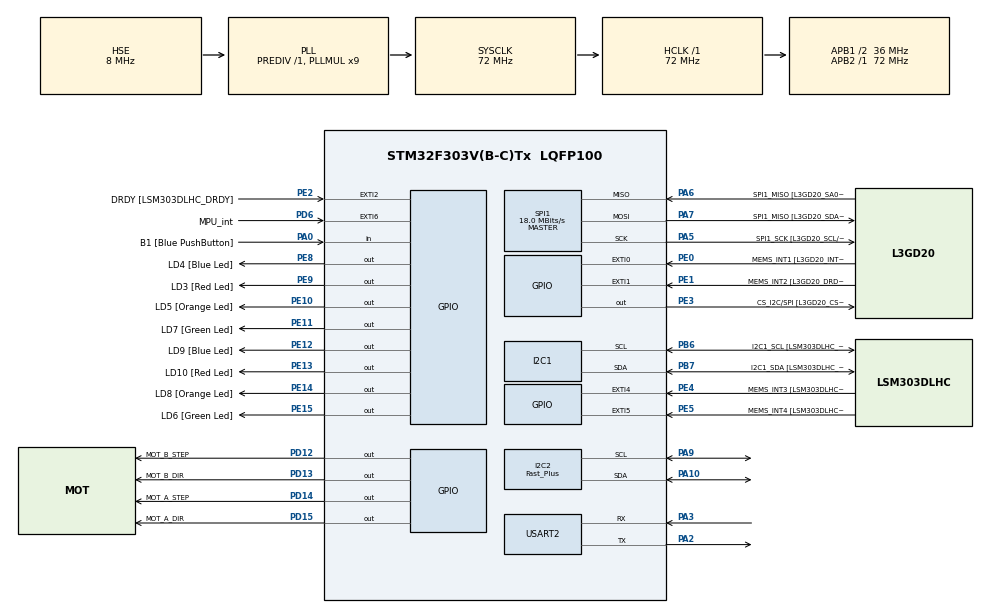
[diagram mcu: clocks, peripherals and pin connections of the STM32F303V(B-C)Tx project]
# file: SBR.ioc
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Dma.I2C2_RX.0.Direction=DMA_PERIPH_TO_MEMORY
Dma.I2C2_RX.0.Instance=DMA1_Channel5
Dma.I2C2_RX.0.MemDataAlignment=DMA_MDATAALIGN_BYTE
Dma.I2C2_RX.0.MemInc=DMA_MINC_ENABLE
Dma.I2C2_RX.0.Mode=DMA_NORMAL
Dma.I2C2_RX.0.PeriphDataAlignment=DMA_PDATAALIGN_BYTE
Dma.I2C2_RX.0.PeriphInc=DMA_PINC_DISABLE
Dma.I2C2_RX.0.Priority=DMA_PRIORITY_LOW
Dma.I2C2_TX.2.Direction=DMA_MEMORY_TO_PERIPH
Dma.I2C2_TX.2.Instance=DMA1_Channel4
Dma.I2C2_TX.2.MemDataAlignment=DMA_MDATAALIGN_BYTE
Dma.I2C2_TX.2.MemInc=DMA_MINC_ENABLE
Dma.I2C2_TX.2.Mode=DMA_NORMAL
Dma.I2C2_TX.2.PeriphDataAlignment=DMA_PDATAALIGN_BYTE
Dma.I2C2_TX.2.PeriphInc=DMA_PINC_DISABLE
Dma.I2C2_TX.2.Priority=DMA_PRIORITY_LOW
Dma.Request0=I2C2_RX
Dma.Request1=USART2_TX
Dma.Request2=I2C2_TX
Dma.Request3=USART2_RX
Dma.USART2_RX.3.Direction=DMA_PERIPH_TO_MEMORY
Dma.USART2_RX.3.Instance=DMA1_Channel6
Dma.USART2_RX.3.MemDataAlignment=DMA_MDATAALIGN_BYTE
Dma.USART2_RX.3.MemInc=DMA_MINC_ENABLE
Dma.USART2_RX.3.Mode=DMA_CIRCULAR
Dma.USART2_RX.3.PeriphDataAlignment=DMA_PDATAALIGN_BYTE
Dma.USART2_RX.3.PeriphInc=DMA_PINC_DISABLE
Dma.USART2_RX.3.Priority=DMA_PRIORITY_LOW
Dma.USART2_TX.1.Direction=DMA_MEMORY_TO_PERIPH
Dma.USART2_TX.1.Instance=DMA1_Channel7
Dma.USART2_TX.1.MemDataAlignment=DMA_MDATAALIGN_BYTE
Dma.USART2_TX.1.MemInc=DMA_MINC_ENABLE
Dma.USART2_TX.1.Mode=DMA_NORMAL
Dma.USART2_TX.1.PeriphDataAlignment=DMA_PDATAALIGN_BYTE
Dma.USART2_TX.1.PeriphInc=DMA_PINC_DISABLE
Dma.USART2_TX.1.Priority=DMA_PRIORITY_LOW
I2C1.Timing-I2C=0x2000090E
I2C2.I2C_Speed_Mode=I2C_Fast_Plus
I2C2.Timing=0x00000001
Mcu.Family=STM32F3
Mcu.Name=STM32F303V(B-C)Tx
Mcu.Package=LQFP100
NVIC.DMA1_Channel4_IRQn=true\:0\:0\:false\:false\:true\:false\:true
NVIC.DMA1_Channel5_IRQn=true\:0\:0\:false\:false\:true\:false\:true
NVIC.DMA1_Channel6_IRQn=true\:0\:0\:false\:false\:true\:false\:true
NVIC.DMA1_Channel7_IRQn=true\:0\:0\:false\:false\:true\:false\:true
NVIC.EXTI9_5_IRQn=true\:0\:0\:false\:false\:true\:true\:true
NVIC.I2C2_EV_IRQn=true\:0\:0\:false\:false\:true\:true\:true
NVIC.PriorityGroup=NVIC_PRIORITYGROUP_0
NVIC.TIM1_UP_TIM16_IRQn=true\:0\:0\:false\:false\:true\:false\:true
NVIC.TIM3_IRQn=true\:0\:0\:false\:false\:true\:true\:true
NVIC.TimeBase=TIM1_UP_TIM16_IRQn
NVIC.TimeBaseIP=TIM1
NVIC.USART2_IRQn=true\:0\:0\:false\:false\:true\:true\:true
PA0.GPIO_Label=B1 [Blue PushButton]
PA0.Signal=GPIO_Input
PA10.Mode=I2C
PA10.Signal=I2C2_SDA
PA11.GPIO_Label=DM
PA11.Signal=USB_DM
PA12.GPIO_Label=DP
PA12.Signal=USB_DP
PA13.GPIO_Label=SWDIO
PA13.Mode=Serial_Wire
PA13.Signal=SYS_JTMS-SWDIO
PA14.GPIO_Label=SWCLK
PA14.Mode=Serial_Wire
PA14.Signal=SYS_JTCK-SWCLK
PA2.Mode=Asynchronous
PA2.Signal=USART2_TX
PA3.Mode=Asynchronous
PA3.Signal=USART2_RX
PA5.GPIO_Label=SPI1_SCK [L3GD20_SCL/SPC]
PA5.Mode=Full_Duplex_Master
PA5.Signal=SPI1_SCK
PA6.GPIO_Label=SPI1_MISO [L3GD20_SA0/SDO]
PA6.Mode=Full_Duplex_Master
PA6.Signal=SPI1_MISO
PA7.GPIO_Label=SPI1_MISO [L3GD20_SDA/SDI/SDO]
PA7.Mode=Full_Duplex_Master
PA7.Signal=SPI1_MOSI
PA9.Mode=I2C
PA9.Signal=I2C2_SCL
PB3.GPIO_Label=SWO
PB3.Signal=SYS_JTDO-TRACESWO
PB6.GPIO_Label=I2C1_SCL [LSM303DLHC_SCL]
PB6.Mode=I2C
PB6.Signal=I2C1_SCL
PB7.GPIO_Label=I2C1_SDA [LSM303DLHC_SDA]
PB7.Mode=I2C
PB7.Signal=I2C1_SDA
PC14-OSC32_IN.GPIO_Label=OSC32_IN
PC14-OSC32_IN.Signal=RCC_OSC32_IN
PC15-OSC32_OUT.GPIO_Label=OSC32_OUT
PC15-OSC32_OUT.Signal=RCC_OSC32_OUT
PD12.GPIO_Label=MOT_B_STEP
PD12.Signal=GPIO_Output
PD13.GPIO_Label=MOT_B_DIR
PD13.Signal=GPIO_Output
PD14.GPIO_Label=MOT_A_STEP
PD14.Signal=GPIO_Output
PD15.GPIO_Label=MOT_A_DIR
PD15.Signal=GPIO_Output
PD6.GPIO_Label=MPU_int
PD6.Signal=GPXTI6
PE0.GPIO_Label=MEMS_INT1 [L3GD20_INT1]
PE0.GPIO_ModeDefaultEXTI=GPIO_MODE_EVT_RISING
PE0.Signal=GPXTI0
PE1.GPIO_Label=MEMS_INT2 [L3GD20_DRDY/INT2]
PE1.GPIO_ModeDefaultEXTI=GPIO_MODE_EVT_RISING
PE1.Signal=GPXTI1
PE10.GPIO_Label=LD5 [Orange Led]
PE10.Signal=GPIO_Output
PE11.GPIO_Label=LD7 [Green Led]
PE11.Signal=GPIO_Output
PE12.GPIO_Label=LD9 [Blue Led]
PE12.Signal=GPIO_Output
PE13.GPIO_Label=LD10 [Red Led]
PE13.Signal=GPIO_Output
PE14.GPIO_Label=LD8 [Orange Led]
PE14.Signal=GPIO_Output
PE15.GPIO_Label=LD6 [Green Led]
PE15.Signal=GPIO_Output
PE2.GPIO_Label=DRDY [LSM303DLHC_DRDY]
PE2.GPIO_ModeDefaultEXTI=GPIO_MODE_EVT_RISING
PE2.Signal=GPXTI2
PE3.GPIO_Label=CS_I2C/SPI [L3GD20_CS_I2C/SPI]
PE3.Signal=GPIO_Output
PE4.GPIO_Label=MEMS_INT3 [LSM303DLHC_INT1]
PE4.GPIO_ModeDefaultEXTI=GPIO_MODE_EVT_RISING
PE4.Signal=GPXTI4
PE5.GPIO_Label=MEMS_INT4 [LSM303DLHC_INT2]
PE5.GPIO_ModeDefaultEXTI=GPIO_MODE_EVT_RISING
PE5.Signal=GPXTI5
PE8.GPIO_Label=LD4 [Blue Led]
PE8.Signal=GPIO_Output
PE9.GPIO_Label=LD3 [Red Led]
PE9.Signal=GPIO_Output
PF0-OSC_IN.GPIO_Label=OSC_IN
PF0-OSC_IN.Mode=HSE-External-Clock-Source
PF0-OSC_IN.Signal=RCC_OSC_IN
PF1-OSC_OUT.GPIO_Label=OSC_OUT
PF1-OSC_OUT.Signal=RCC_OSC_OUT
ProjectManager.HeapSize=0x200
ProjectManager.StackSize=0x400
ProjectManager.TargetToolchain=Other Toolchains (GPDSC)
RCC.AHBFreq_Value=72000000
RCC.APB1CLKDivider=RCC_HCLK_DIV2
RCC.APB1Freq_Value=36000000
RCC.APB1TimFreq_Value=72000000
RCC.APB2Freq_Value=72000000
RCC.APB2TimFreq_Value=72000000
RCC.CortexFreq_Value=72000000
RCC.HCLKFreq_Value=72000000
RCC.HSE_VALUE=8000000
RCC.HSI_VALUE=8000000
RCC.LSE_VALUE=32768
RCC.PLLMUL=RCC_PLL_MUL9
RCC.PLLSourceVirtual=RCC_PLLSOURCE_HSE
RCC.PRESCALERUSB=RCC_USBCLKSOURCE_PLL_DIV1_5
RCC.SYSCLKFreq_VALUE=72000000
RCC.SYSCLKSourceVirtual=RCC_SYSCLKSOURCE_PLLCLK
RCC.USBFreq_Value=48000000
SPI1.BaudRatePrescaler=SPI_BAUDRATEPRESCALER_4
SPI1.BaudRatePrescaler-Full_Duplex_Master=SPI_BAUDRATEPRESCALER_2
SPI1.CalculateBaudRate=18.0 MBits/s
SPI1.CalculateBaudRate-Full_Duplex_Master=24.0 MBits/s
SPI1.Direction=SPI_DIRECTION_2LINES
SPI1.Mode=SPI_MODE_MASTER
SPI1.Mode-Full_Duplex_Master=SPI_MODE_MASTER
SPI1.VirtualType=VM_MASTER
USART2.VirtualMode-Asynchronous=VM_ASYNC
VP_CRC_VS_CRC.Mode=CRC_Activate
VP_SYS_VS_tim1.Mode=TIM1
VP_TIM3_VS_ClockSourceINT.Mode=Internal
board=STM32F3DISCOVERY

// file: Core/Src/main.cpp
/* USER CODE BEGIN Header */
/**
  ******************************************************************************
  * @file           : main.c
  * @brief          : Main program body
  ******************************************************************************
  * @attention
  *
  * <h2><center>&copy; Copyright (c) 2023 STMicroelectronics.
  * All rights reserved.</center></h2>
  *
  * This software component is licensed by ST under BSD 3-Clause license,
  * the "License"; You may not use this file except in compliance with the
  * License. You may obtain a copy of the License at:
  *                        opensource.org/licenses/BSD-3-Clause
  *
  ******************************************************************************
  */
/* USER CODE END Header */
#include "main.h"
#include <string.h>
#include "mpu6050.h"
#include "ssd1306.h"
#include "PID.h"
#include "stdio.h"
/* USER CODE BEGIN Includes */

#define PPR   1600
// #define TICKS_PER_SECOND  40000 // 40kHz
#define TICKS_PER_SECOND  50000 // 50kHz
#define PULSE_WIDTH 1

#define MAX_ACCEL (200)
#define ANGLE_Kp  450.0
#define ANGLE_Kd  30.0
#define ANGLE_Ki  0.0
#define MAX_ACCEL (200)

#define VELOCITY_Kp  0.007
#define VELOCITY_Kd  0.0
#define VELOCITY_Ki  0.0005
#define WARMUP_DELAY_US (5000000UL)
#define DEG_TO_RAD  0.017453292519943295769236907684886
#define RAD_TO_DEG  57.295779513082320876798154814105
#define ANGLE_SET_POINT (2.0 * DEG_TO_RAD)
#define constrain(amt,low,high) ((amt)<(low)?(low):((amt)>(high)?(high):(amt)))

#define MAX_PACKET_SIZE 96
#define DIVISOR 10000.0

CRC_HandleTypeDef hcrc;

I2C_HandleTypeDef hi2c1;
I2C_HandleTypeDef hi2c2;
DMA_HandleTypeDef hdma_i2c2_rx;
DMA_HandleTypeDef hdma_i2c2_tx;
SPI_HandleTypeDef hspi1;
TIM_HandleTypeDef htim3;
UART_HandleTypeDef huart2;
DMA_HandleTypeDef hdma_usart2_tx;
DMA_HandleTypeDef hdma_usart2_rx;

/* USER CODE BEGIN PV */
int16_t acc_x, acc_y, acc_z, gyr_x, gyr_y, gyr_z;
float ax, ay, az, gx, gy, gz, temperature, roll, pitch;
uint8_t buffer[128];

volatile bool i2c2_transmit_complete = false;
volatile bool i2c2_receive_complete = false;

volatile bool mpuInterrupt = false;

uint8_t fifoBuffer[64];

Quaternion q; // [w, x, y, z]         quaternion container
VectorFloat gravity; // [x, y, z]            gravity vector
float ypr[3]; // [yaw, pitch, roll]   yaw/pitch/roll container and gravity vector

PID anglePID(ANGLE_Kp, ANGLE_Kd, ANGLE_Ki, ANGLE_SET_POINT);
PID velocityPID(VELOCITY_Kp, VELOCITY_Kd, VELOCITY_Ki, 0.0);

float pid_settings[6] = {
	ANGLE_Kp,
	ANGLE_Kd,
	ANGLE_Ki,
	VELOCITY_Kp,
	VELOCITY_Kd,
	VELOCITY_Ki
};

volatile unsigned long currentTickLeft = 0UL;
volatile unsigned long currentTickRight = 0UL;
volatile unsigned long ticksPerPulseLeft = (unsigned long)UINT64_MAX;
volatile unsigned long ticksPerPulseRight = (unsigned long)UINT64_MAX;
volatile float accel = 0.0;
volatile float velocity = 0.0;

float joystick[2] = { 0.0f, 0.0f };
float ref_velocity = 0.0f;
float ref_steering = 0.0f;
float steering = 0.0f;

float angle = 0.0;
float targetAngle = ANGLE_SET_POINT;

float targetVelocity = 0.0;

bool isBalancing = false;

char packet[MAX_PACKET_SIZE];
uint8_t packet_size = 0;

/*uint8_t rxBuffer[64];
uint8_t rxByte;
uint16_t rxIdx;
uint8_t rxFlag;*/

#define CIRC_BUF_SZ       64  /* must be power of two */
static uint8_t rx_dma_circ_buf[CIRC_BUF_SZ];
#define DMA_WRITE_PTR ( (CIRC_BUF_SZ - huart2.hdmarx->Instance->CNDTR) & (CIRC_BUF_SZ - 1) )
static uint32_t rd_ptr;
/* USER CODE END PV */

void SystemClock_Config(void);
static void MX_GPIO_Init(void);
static void MX_DMA_Init(void);
static void MX_I2C1_Init(void);
static void MX_SPI1_Init(void);
static void MX_I2C2_Init(void);
static void MX_USART2_UART_Init(void);
static void MX_CRC_Init(void);
static void MX_TIM3_Init(void);

uint32_t getCurrentMicros(void)
{
	uint32_t m0 = HAL_GetTick();
	__IO uint32_t u0 = SysTick->VAL;
	uint32_t m1 = HAL_GetTick();
	__IO uint32_t u1 = SysTick->VAL;
	const uint32_t tms = SysTick->LOAD + 1;

	if (m1 != m0) {
		return (m1 * 1000 + ((tms - u1) * 1000) / tms);
	}
	else {
		return (m0 * 1000 + ((tms - u0) * 1000) / tms);
	}
}

void UART2_SendString(char* s)
{
	HAL_UART_Transmit(&huart2, (uint8_t*)s, strlen(s), 1000);
}

void send_float_array(float *a, uint8_t size) {
	char MSG[40] = { '\0' };
	for (int i = 0; i < size; i++) {
		sprintf(MSG, "%.2ld", (long)(a[i] * DIVISOR));
		//Serial.print((long)(a[i] * DIVISOR));
		UART2_SendString(MSG);
		if (i < size - 1) {
			MSG[0] = ';';
			MSG[1] = '\0';
			UART2_SendString(MSG);
			//Serial.print(';');
		}
	}
	//Serial.print("\r\n");
	MSG[0] = '\r';
	MSG[1] = '\n';
	MSG[1] = '\0';
	UART2_SendString(MSG);
}

void logDisplay(unsigned long nowMicros) {
	char MSG[40] = { '\0' };
	static unsigned long timestamp = HAL_GetTick();
	if (nowMicros - timestamp < 10000 /* 100Hz */) {
		return;
	}
	HAL_GPIO_TogglePin(GPIOE, LD3_Pin);

	ssd1306_Clear();

	//sprintf((char*)buffer, "ACC: X: %.2f Y:%.2f Z:%.2f \n\rGYR: X: %.2f Y:%.2f Z:%.2f\n\rTEMP: %.2f\n\r", ax, ay, az, gx, gy, gz, temperature);

	sprintf(MSG, "Angle: %.2f", angle * RAD_TO_DEG);
	ssd1306_SetCursor(0, 0);
	ssd1306_WriteString(MSG, Font_7x10);

	sprintf(MSG, "TAngle: %.2f", targetAngle * RAD_TO_DEG);
	ssd1306_SetCursor(0, 10);
	ssd1306_WriteString(MSG, Font_7x10);

	sprintf(MSG, "Velocity: %.4f", ref_velocity);
	ssd1306_SetCursor(0, 20);
	ssd1306_WriteString(MSG, Font_7x10);

	//sprintf((char*)buffer, "RPY: Roll: %.2f Pitch: %.2f\n\r\n\r", roll, pitch);

	sprintf(MSG, "Steering: %.4f", ref_steering);
	ssd1306_SetCursor(0, 30);
	ssd1306_WriteString(MSG, Font_7x10);

	/*sprintf(MSG, "Gy: %8.4f", ((s32)gy) * 2000.0 / 32768);
	ssd1306_SetCursor(0, 40);
	ssd1306_WriteString(MSG, Font_7x10);

	sprintf(MSG, "Gz: %8.4f", ((s32)gz) * 2000.0 / 32768);
	ssd1306_SetCursor(0, 50);
	ssd1306_WriteString(MSG, Font_7x10);
	ssd1306_UpdateScreen();
	//timestamp = nowMicros;

	printf("accel: (%8.4f, %8.4f, %8.4f)     gyro: (%12.4f, %12.4f, %12.4f)\r\n",
		((s32)ax) * 16.0 / 32768,
		((s32)ay) * 16.0 / 32768,
		((s32)az) * 16.0 / 32768,
		((s32)gx) * 2000.0 / 32768,
		((s32)gy) * 2000.0 / 32768,
		((s32)gz) * 2000.0 / 32768);*/

	/*float t = (float)(targetAngle * RAD_TO_DEG);
	sprintf(MSG, "a0: %.4f", t);
	ssd1306_SetCursor(0, 0);
	ssd1306_WriteString(MSG, Font_7x10);

	t = (float)(angle * RAD_TO_DEG);
	sprintf(MSG, "ta: %.4f", t);
	ssd1306_SetCursor(0, 10);
	ssd1306_WriteString(MSG, Font_7x10);

	sprintf(MSG, "tv: %.4f", velocity);
	ssd1306_SetCursor(0, 20);
	ssd1306_WriteString(MSG, Font_7x10);

	sprintf(MSG, "tu: %.4f", accel);
	ssd1306_SetCursor(0, 30);
	ssd1306_WriteString(MSG, Font_7x10);
	ssd1306_UpdateScreen();
	timestamp = nowMicros;*/
	timestamp = nowMicros;
	ssd1306_UpdateScreen();
}

void initMPU() {
	const int16_t accel_offset[3] = { -1262, -307, 1897 };
	const int16_t gyro_offset[3] = { 23, -41, 49 };

	if (MPU6050_Init(&hi2c2)) {
		ssd1306_Clear();
		ssd1306_SetCursor(0, 0);
		ssd1306_WriteString("MPU: OK", Font_7x10);
		ssd1306_UpdateScreen();

	}
	else {
		ssd1306_Clear();
		ssd1306_SetCursor(0, 0);
		ssd1306_WriteString("MPU: FAULT", Font_7x10);
		ssd1306_UpdateScreen();
		while (1)
		{}
	}

	HAL_Delay(1000);

	if (!MPU6050_dmpInitialize()) {
		ssd1306_SetCursor(0, 10);
		ssd1306_WriteString("DMP: OK", Font_7x10);
		ssd1306_UpdateScreen();

	}
	else {
		ssd1306_SetCursor(0, 10);
		ssd1306_WriteString("DMP: FAULT", Font_7x10);
		ssd1306_UpdateScreen();
		while (1)
		{}
	}

	HAL_Delay(1000);

	//MPU6050_dmpInitialize();

	/*mpu.setXGyroOffset(gyro_offset[0]);
	mpu.setYGyroOffset(gyro_offset[1]);
	mpu.setZGyroOffset(gyro_offset[2]);
	mpu.setXAccelOffset(accel_offset[0]);
	mpu.setYAccelOffset(accel_offset[1]);
	mpu.setZAccelOffset(accel_offset[2]);*/

	MPU6050_setDMPEnabled(true);
	/* EXTI interrupt init*/
	HAL_NVIC_SetPriority(EXTI9_5_IRQn, 0, 0);
	HAL_NVIC_EnableIRQ(EXTI9_5_IRQn);
}

bool mpuUpdate() {
	if (mpuInterrupt && MPU6050_GetCurrentFIFOPacket(fifoBuffer, dmpPacketSize)) {
		MPU6050_dmpGetQuaternion(&q, fifoBuffer);
		MPU6050_dmpGetGravity(&gravity, &q);
		MPU6050_dmpGetYawPitchRoll(ypr, &q, &gravity);
		mpuInterrupt = false;
		return true;
	}
	return false;
}

unsigned long getTicksPerPulse(float velocity) {
	if (abs(velocity) < 1e-3) {
		// TODO: disable motor
		return (unsigned long)UINT64_MAX ;
	}
	else {
		return (uint64_t)(2.0 * M_PI * TICKS_PER_SECOND / (abs(velocity) * PPR)) - PULSE_WIDTH;
	}
}
void updateVelocity(unsigned long nowMicros) {
	// static unsigned long counter = 0;
	// static unsigned long sum = 0;

	static unsigned long timestamp = getCurrentMicros();
	if (nowMicros - timestamp < 100 /* 10kHz */) {
		return;
	}

	// sum += (nowMicros - timestamp);
	// counter++;
	// if (counter >= 1000) {
	//   Serial.println(((float)(sum)) / counter);
	//   counter = 0;
	//   sum = 0;
	// }

	float dt = ((float)(nowMicros - timestamp)) * 1e-6;
	velocity += accel * dt;

	float leftVelocity = velocity - steering;
	float rightVelocity = velocity + steering;
	ticksPerPulseLeft = getTicksPerPulse(leftVelocity);
	ticksPerPulseRight = getTicksPerPulse(rightVelocity);

	if (leftVelocity > 0) {
		//digitalWrite(MOT_A_DIR, HIGH);
		HAL_GPIO_WritePin(GPIOD, MOT_A_DIR_Pin, GPIO_PIN_SET);

	}
	else {
		HAL_GPIO_WritePin(GPIOD, MOT_A_DIR_Pin, GPIO_PIN_RESET);
		//digitalWrite(MOT_A_DIR, LOW);
	}

	if (rightVelocity > 0) {
		HAL_GPIO_WritePin(GPIOD, MOT_B_DIR_Pin, GPIO_PIN_RESET);
		//digitalWrite(MOT_B_DIR, LOW);
	}
	else {
		HAL_GPIO_WritePin(GPIOD, MOT_B_DIR_Pin, GPIO_PIN_SET);
		//digitalWrite(MOT_B_DIR, HIGH);
	}

	timestamp = nowMicros;
}

float absF(float value)
{
	return value < 0 ? -value : value;
}

void updateControl(unsigned long nowMicros) {
	/* Wait until IMU filter will settle */
	if (nowMicros < WARMUP_DELAY_US) {
		return;
	}

	static unsigned long timestamp = HAL_GetTick();
	if (nowMicros - timestamp < 1000 /* 1kHz */) {
		return;
	}
	if (!mpuUpdate()) {
		return;
	}
	angle = ypr[1];

	float dt = ((float)(nowMicros - timestamp)) * 1e-6;
	float tmpangle = absF(angle - targetAngle);
	if (tmpangle < M_PI / 18) {
		isBalancing = true;
	}

	if (tmpangle > M_PI / 4) {
		isBalancing = false;
		accel = 0.0;
		velocity = 0.0;
	}

	if (!isBalancing) {
		return;
	}
	targetAngle = -velocityPID.getControl(velocity, dt);
	anglePID.setTarget(targetAngle);

	accel = anglePID.getControl(angle, dt);
	accel = constrain(accel, -MAX_ACCEL, MAX_ACCEL);

	timestamp = nowMicros;
}

void initMotors() {

	HAL_GPIO_WritePin(GPIOD, MOT_A_STEP_Pin, GPIO_PIN_RESET);
	HAL_GPIO_WritePin(GPIOD, MOT_B_STEP_Pin, GPIO_PIN_RESET);
	HAL_GPIO_WritePin(GPIOD, MOT_ENABLE_Pin, GPIO_PIN_RESET);
}

void parse_float_array(char *p, uint8_t p_size, float *dest) {
	char buf[16];
	long value;
	uint8_t buf_size = 0;
	uint8_t index = 0;
	for (uint8_t i = 0; i < p_size; i++) {
		if ((p[i] >= '0' && p[i] <= '9') || p[i] == '+' || p[i] == '-') {
			buf[buf_size++] = p[i];
		}
		else if (p[i] == ';') {
			buf[buf_size] = '\0';
			buf_size = 0;
			value = atol(buf);
			dest[index++] = ((float)value) / DIVISOR;
		}
	}
	buf[buf_size] = '\0';
	value = atol(buf);
	dest[index] = ((float)value) / DIVISOR;
}

void parse_settings(char *p, uint8_t p_size) {
	parse_float_array(p, p_size, pid_settings);
	anglePID.setSettings(pid_settings[0], pid_settings[1], pid_settings[2]);
	velocityPID.setSettings(pid_settings[3], pid_settings[4], pid_settings[5]);
}

void parse_control(char *p, uint8_t p_size) {
	parse_float_array(p, p_size, joystick);
	ref_velocity = joystick[0];
	ref_steering = joystick[1];
}

void handle_packet(char *p, uint8_t p_size) {
	switch (p[0]) {
	case 'r':
		send_float_array(pid_settings, 6);
		break;
	case 's':
		parse_settings(&p[1], p_size - 1);
		send_float_array(pid_settings, 6);
		break;
	case 'c':
		parse_control(&p[1], p_size - 1);
		//send_float_array(joystick, 2);
		break;
	}
}

static bool msgrx_circ_buf_is_empty(void) {
	if (rd_ptr == DMA_WRITE_PTR) {
		return true;
	}
	return false;
}

static uint8_t msgrx_circ_buf_get(void) {
	uint8_t c = 0;
	if (rd_ptr != DMA_WRITE_PTR) {
		c = rx_dma_circ_buf[rd_ptr++];
		rd_ptr &= (CIRC_BUF_SZ - 1);
	}
	return c;
}
int main(void)
{

	/* MCU Configuration--------------------------------------------------------*/

	/* Reset of all peripherals, Initializes the Flash interface and the Systick. */
	HAL_Init();

	/* Configure the system clock */
	SystemClock_Config();

	/* Initialize all configured peripherals */
	MX_GPIO_Init();
	MX_DMA_Init();
	MX_I2C1_Init();
	MX_SPI1_Init();
	MX_I2C2_Init();
	MX_USART2_UART_Init();
	MX_CRC_Init();
	MX_TIM3_Init();
	/* USER CODE BEGIN 2 */
	ssd1306_Init();
	ssd1306_FlipScreenVertically();
	ssd1306_Clear();
	ssd1306_SetColor(White);

	ssd1306_DrawRect(0, 0, ssd1306_GetWidth(), ssd1306_GetHeight());
	ssd1306_SetCursor(8, 20);
	ssd1306_WriteString("MPU6050", Font_16x26);
	ssd1306_UpdateScreen();
	HAL_Delay(2000);
	ssd1306_Clear();
	ssd1306_UpdateScreen();
	ssd1306_Clear();
	ssd1306_SetCursor(0, 0);
	ssd1306_WriteString("* FIRMWARE RESET *", Font_7x10);
	ssd1306_UpdateScreen();

	initMPU();
	initMotors();
	/* USER CODE END 2 */
	HAL_TIM_Base_Start_IT(&htim3);

	HAL_NVIC_SetPriority(USART2_IRQn, 0, 0);
	HAL_NVIC_EnableIRQ(USART2_IRQn);
	HAL_UART_Receive_DMA(&huart2, rx_dma_circ_buf, CIRC_BUF_SZ);

	/* Infinite loop */
	/* USER CODE BEGIN WHILE */
	while (1)
	{
		unsigned long now = getCurrentMicros();
		updateVelocity(now);
		updateControl(now);
#ifdef LOGGING_ENABLED
		logDisplay(now);
#endif

#ifdef COUNT_LOOP
		static unsigned long last_ts = micros();
		static unsigned long  counter = 0;

		counter++;
		if (now - last_ts >= 1000000) {
			Serial.println(counter);
			counter = 0;
			last_ts = now;
		}
#endif

		while (!msgrx_circ_buf_is_empty())
		{
			uint8_t c = msgrx_circ_buf_get();
			//HAL_UART_Receive(&huart2, &c, 1, 1000);

			if (c == '\n') {
				continue;
			}
			else if (c == '\r') {
				handle_packet(packet, packet_size);
				packet_size = 0;
			}
			else {
				packet[packet_size++] = (uint8_t) c;
			}
		}
		static const float a = 0.99;
		targetVelocity = a * targetVelocity + (1.0 - a) * ref_velocity;
		velocityPID.setTarget(targetVelocity);

		steering = a * steering + (1.0 - a) * ref_steering;
	}
	/* USER CODE END 3 */
}

void SystemClock_Config(void)
{
	RCC_OscInitTypeDef RCC_OscInitStruct = { 0 };
	RCC_ClkInitTypeDef RCC_ClkInitStruct = { 0 };
	RCC_PeriphCLKInitTypeDef PeriphClkInit = { 0 };

	/** Initializes the RCC Oscillators according to the specified parameters
	* in the RCC_OscInitTypeDef structure.
	*/
	RCC_OscInitStruct.OscillatorType = RCC_OSCILLATORTYPE_HSI | RCC_OSCILLATORTYPE_HSE;
	RCC_OscInitStruct.HSEState = RCC_HSE_BYPASS;
	RCC_OscInitStruct.HSEPredivValue = RCC_HSE_PREDIV_DIV1;
	RCC_OscInitStruct.HSIState = RCC_HSI_ON;
	RCC_OscInitStruct.HSICalibrationValue = RCC_HSICALIBRATION_DEFAULT;
	RCC_OscInitStruct.PLL.PLLState = RCC_PLL_ON;
	RCC_OscInitStruct.PLL.PLLSource = RCC_PLLSOURCE_HSE;
	RCC_OscInitStruct.PLL.PLLMUL = RCC_PLL_MUL9;
	if (HAL_RCC_OscConfig(&RCC_OscInitStruct) != HAL_OK)
	{
		Error_Handler();
	}
	/** Initializes the CPU, AHB and APB buses clocks
	*/
	RCC_ClkInitStruct.ClockType = RCC_CLOCKTYPE_HCLK | RCC_CLOCKTYPE_SYSCLK
	                            | RCC_CLOCKTYPE_PCLK1 | RCC_CLOCKTYPE_PCLK2;
	RCC_ClkInitStruct.SYSCLKSource = RCC_SYSCLKSOURCE_PLLCLK;
	RCC_ClkInitStruct.AHBCLKDivider = RCC_SYSCLK_DIV1;
	RCC_ClkInitStruct.APB1CLKDivider = RCC_HCLK_DIV2;
	RCC_ClkInitStruct.APB2CLKDivider = RCC_HCLK_DIV1;

	if (HAL_RCC_ClockConfig(&RCC_ClkInitStruct, FLASH_LATENCY_2) != HAL_OK)
	{
		Error_Handler();
	}
	PeriphClkInit.PeriphClockSelection = RCC_PERIPHCLK_USART2 | RCC_PERIPHCLK_I2C1
	                            | RCC_PERIPHCLK_I2C2;
	PeriphClkInit.Usart2ClockSelection = RCC_USART2CLKSOURCE_PCLK1;
	PeriphClkInit.I2c1ClockSelection = RCC_I2C1CLKSOURCE_HSI;
	PeriphClkInit.I2c2ClockSelection = RCC_I2C2CLKSOURCE_HSI;
	if (HAL_RCCEx_PeriphCLKConfig(&PeriphClkInit) != HAL_OK)
	{
		Error_Handler();
	}
}

static void MX_CRC_Init(void)
{

	hcrc.Instance = CRC;
	hcrc.Init.DefaultPolynomialUse = DEFAULT_POLYNOMIAL_ENABLE;
	hcrc.Init.DefaultInitValueUse = DEFAULT_INIT_VALUE_ENABLE;
	hcrc.Init.InputDataInversionMode = CRC_INPUTDATA_INVERSION_NONE;
	hcrc.Init.OutputDataInversionMode = CRC_OUTPUTDATA_INVERSION_DISABLE;
	hcrc.InputDataFormat = CRC_INPUTDATA_FORMAT_BYTES;
	if (HAL_CRC_Init(&hcrc) != HAL_OK)
	{
		Error_Handler();
	}

}

static void MX_I2C1_Init(void)
{

	hi2c1.Instance = I2C1;
	hi2c1.Init.Timing = 0x2000090E;
	hi2c1.Init.OwnAddress1 = 0;
	hi2c1.Init.AddressingMode = I2C_ADDRESSINGMODE_7BIT;
	hi2c1.Init.DualAddressMode = I2C_DUALADDRESS_DISABLE;
	hi2c1.Init.OwnAddress2 = 0;
	hi2c1.Init.OwnAddress2Masks = I2C_OA2_NOMASK;
	hi2c1.Init.GeneralCallMode = I2C_GENERALCALL_DISABLE;
	hi2c1.Init.NoStretchMode = I2C_NOSTRETCH_DISABLE;
	if (HAL_I2C_Init(&hi2c1) != HAL_OK)
	{
		Error_Handler();
	}
	/** Configure Analogue filter
	*/
	if (HAL_I2CEx_ConfigAnalogFilter(&hi2c1, I2C_ANALOGFILTER_ENABLE) != HAL_OK)
	{
		Error_Handler();
	}
	/** Configure Digital filter
	*/
	if (HAL_I2CEx_ConfigDigitalFilter(&hi2c1, 0) != HAL_OK)
	{
		Error_Handler();
	}

}

static void MX_I2C2_Init(void)
{

	hi2c2.Instance = I2C2;
	hi2c2.Init.Timing = 0x00000001;
	hi2c2.Init.OwnAddress1 = 0;
	hi2c2.Init.AddressingMode = I2C_ADDRESSINGMODE_7BIT;
	hi2c2.Init.DualAddressMode = I2C_DUALADDRESS_DISABLE;
	hi2c2.Init.OwnAddress2 = 0;
	hi2c2.Init.OwnAddress2Masks = I2C_OA2_NOMASK;
	hi2c2.Init.GeneralCallMode = I2C_GENERALCALL_DISABLE;
	hi2c2.Init.NoStretchMode = I2C_NOSTRETCH_DISABLE;
	if (HAL_I2C_Init(&hi2c2) != HAL_OK)
	{
		Error_Handler();
	}
	/** Configure Analogue filter
	*/
	if (HAL_I2CEx_ConfigAnalogFilter(&hi2c2, I2C_ANALOGFILTER_ENABLE) != HAL_OK)
	{
		Error_Handler();
	}
	/** Configure Digital filter
	*/
	if (HAL_I2CEx_ConfigDigitalFilter(&hi2c2, 0) != HAL_OK)
	{
		Error_Handler();
	}
	/** I2C Fast mode Plus enable
	*/
	__HAL_SYSCFG_FASTMODEPLUS_ENABLE(I2C_FASTMODEPLUS_I2C2);

}

static void MX_SPI1_Init(void)
{

	/* SPI1 parameter configuration*/
	hspi1.Instance = SPI1;
	hspi1.Init.Mode = SPI_MODE_MASTER;
	hspi1.Init.Direction = SPI_DIRECTION_2LINES;
	hspi1.Init.DataSize = SPI_DATASIZE_4BIT;
	hspi1.Init.CLKPolarity = SPI_POLARITY_LOW;
	hspi1.Init.CLKPhase = SPI_PHASE_1EDGE;
	hspi1.Init.NSS = SPI_NSS_SOFT;
	hspi1.Init.BaudRatePrescaler = SPI_BAUDRATEPRESCALER_4;
	hspi1.Init.FirstBit = SPI_FIRSTBIT_MSB;
	hspi1.Init.TIMode = SPI_TIMODE_DISABLE;
	hspi1.Init.CRCCalculation = SPI_CRCCALCULATION_DISABLE;
	hspi1.Init.CRCPolynomial = 7;
	hspi1.Init.CRCLength = SPI_CRC_LENGTH_DATASIZE;
	hspi1.Init.NSSPMode = SPI_NSS_PULSE_ENABLE;
	if (HAL_SPI_Init(&hspi1) != HAL_OK)
	{
		Error_Handler();
	}

}

static void MX_TIM3_Init(void)
{

	TIM_ClockConfigTypeDef sClockSourceConfig = { 0 };
	TIM_MasterConfigTypeDef sMasterConfig = { 0 };

	htim3.Instance = TIM3;
	htim3.Init.Prescaler = 0;
	htim3.Init.CounterMode = TIM_COUNTERMODE_UP;
	htim3.Init.Period = 4000;
	htim3.Init.ClockDivision = TIM_CLOCKDIVISION_DIV2;
	htim3.Init.AutoReloadPreload = TIM_AUTORELOAD_PRELOAD_DISABLE;
	if (HAL_TIM_Base_Init(&htim3) != HAL_OK)
	{
		Error_Handler();
	}
	sClockSourceConfig.ClockSource = TIM_CLOCKSOURCE_INTERNAL;
	if (HAL_TIM_ConfigClockSource(&htim3, &sClockSourceConfig) != HAL_OK)
	{
		Error_Handler();
	}
	sMasterConfig.MasterOutputTrigger = TIM_TRGO_RESET;
	sMasterConfig.MasterSlaveMode = TIM_MASTERSLAVEMODE_DISABLE;
	if (HAL_TIMEx_MasterConfigSynchronization(&htim3, &sMasterConfig) != HAL_OK)
	{
		Error_Handler();
	}

}

static void MX_USART2_UART_Init(void)
{

	huart2.Instance = USART2;
	huart2.Init.BaudRate = 38400;
	huart2.Init.WordLength = UART_WORDLENGTH_8B;
	huart2.Init.StopBits = UART_STOPBITS_1;
	huart2.Init.Parity = UART_PARITY_NONE;
	huart2.Init.Mode = UART_MODE_TX_RX;
	huart2.Init.HwFlowCtl = UART_HWCONTROL_NONE;
	huart2.Init.OverSampling = UART_OVERSAMPLING_16;
	huart2.Init.OneBitSampling = UART_ONE_BIT_SAMPLE_DISABLE;
	huart2.AdvancedInit.AdvFeatureInit = UART_ADVFEATURE_NO_INIT;
	if (HAL_UART_Init(&huart2) != HAL_OK)
	{
		Error_Handler();
	}
	/* USER CODE BEGIN USART2_Init 2 */
	//HAL_NVIC_SetPriority(USART2_IRQn, 0, 0);
	//HAL_NVIC_EnableIRQ(USART2_IRQn);
	/* USER CODE END USART2_Init 2 */

}

static void MX_DMA_Init(void)
{

	/* DMA controller clock enable */
	__HAL_RCC_DMA1_CLK_ENABLE();

	/* DMA interrupt init */
	/* DMA1_Channel4_IRQn interrupt configuration */
	HAL_NVIC_SetPriority(DMA1_Channel4_IRQn, 0, 0);
	HAL_NVIC_EnableIRQ(DMA1_Channel4_IRQn);
	/* DMA1_Channel5_IRQn interrupt configuration */
	HAL_NVIC_SetPriority(DMA1_Channel5_IRQn, 0, 0);
	HAL_NVIC_EnableIRQ(DMA1_Channel5_IRQn);
	/* DMA1_Channel6_IRQn interrupt configuration */
	HAL_NVIC_SetPriority(DMA1_Channel6_IRQn, 0, 0);
	HAL_NVIC_EnableIRQ(DMA1_Channel6_IRQn);
	/* DMA1_Channel7_IRQn interrupt configuration */
	HAL_NVIC_SetPriority(DMA1_Channel7_IRQn, 0, 0);
	HAL_NVIC_EnableIRQ(DMA1_Channel7_IRQn);

}

static void MX_GPIO_Init(void)
{
	GPIO_InitTypeDef GPIO_InitStruct = { 0 };

	/* GPIO Ports Clock Enable */
	__HAL_RCC_GPIOE_CLK_ENABLE();
	__HAL_RCC_GPIOC_CLK_ENABLE();
	__HAL_RCC_GPIOF_CLK_ENABLE();
	__HAL_RCC_GPIOA_CLK_ENABLE();
	__HAL_RCC_GPIOD_CLK_ENABLE();
	__HAL_RCC_GPIOB_CLK_ENABLE();

	/*Configure GPIO pin Output Level */
	HAL_GPIO_WritePin(GPIOE,
		CS_I2C_SPI_Pin|LD4_Pin|LD3_Pin|LD5_Pin
	                        |LD7_Pin|LD9_Pin|LD10_Pin|LD8_Pin
	                        |LD6_Pin,
		GPIO_PIN_RESET);

	/*Configure GPIO pin Output Level */
	HAL_GPIO_WritePin(GPIOD, MOT_B_STEP_Pin | MOT_B_DIR_Pin | MOT_A_STEP_Pin | MOT_A_DIR_Pin, GPIO_PIN_RESET);
	HAL_GPIO_WritePin(GPIOD, MOT_ENABLE_Pin, GPIO_PIN_SET);
	/*Configure GPIO pins : DRDY_Pin MEMS_INT3_Pin MEMS_INT4_Pin MEMS_INT1_Pin
	                         MEMS_INT2_Pin */
	GPIO_InitStruct.Pin = DRDY_Pin | MEMS_INT3_Pin | MEMS_INT4_Pin | MEMS_INT1_Pin
	                        | MEMS_INT2_Pin;
	GPIO_InitStruct.Mode = GPIO_MODE_EVT_RISING;
	GPIO_InitStruct.Pull = GPIO_NOPULL;
	HAL_GPIO_Init(GPIOE, &GPIO_InitStruct);

	/*Configure GPIO pins : CS_I2C_SPI_Pin LD4_Pin LD3_Pin LD5_Pin
	                         LD7_Pin LD9_Pin LD10_Pin LD8_Pin
	                         LD6_Pin */
	GPIO_InitStruct.Pin = CS_I2C_SPI_Pin | LD4_Pin | LD3_Pin | LD5_Pin
	                        | LD7_Pin | LD9_Pin | LD10_Pin | LD8_Pin
	                        | LD6_Pin;
	GPIO_InitStruct.Mode = GPIO_MODE_OUTPUT_PP;
	GPIO_InitStruct.Pull = GPIO_NOPULL;
	GPIO_InitStruct.Speed = GPIO_SPEED_FREQ_LOW;
	HAL_GPIO_Init(GPIOE, &GPIO_InitStruct);

	/*Configure GPIO pin : B1_Pin */
	GPIO_InitStruct.Pin = B1_Pin;
	GPIO_InitStruct.Mode = GPIO_MODE_INPUT;
	GPIO_InitStruct.Pull = GPIO_NOPULL;
	HAL_GPIO_Init(B1_GPIO_Port, &GPIO_InitStruct);

	/*Configure GPIO pins : MOT_B_STEP_Pin MOT_B_DIR_Pin MOT_A_STEP_Pin MOT_A_DIR_Pin */
	GPIO_InitStruct.Pin = MOT_B_STEP_Pin | MOT_B_DIR_Pin | MOT_A_STEP_Pin | MOT_A_DIR_Pin | MOT_ENABLE_Pin;
	GPIO_InitStruct.Mode = GPIO_MODE_OUTPUT_PP;
	GPIO_InitStruct.Pull = GPIO_NOPULL;
	GPIO_InitStruct.Speed = GPIO_SPEED_FREQ_LOW;
	HAL_GPIO_Init(GPIOD, &GPIO_InitStruct);

	/*Configure GPIO pins : DM_Pin DP_Pin */
	GPIO_InitStruct.Pin = DM_Pin | DP_Pin;
	GPIO_InitStruct.Mode = GPIO_MODE_AF_PP;
	GPIO_InitStruct.Pull = GPIO_NOPULL;
	GPIO_InitStruct.Speed = GPIO_SPEED_FREQ_HIGH;
	GPIO_InitStruct.Alternate = GPIO_AF14_USB;
	HAL_GPIO_Init(GPIOA, &GPIO_InitStruct);

	/*Configure GPIO pin : MPU_int_Pin */
	GPIO_InitStruct.Pin = MPU_int_Pin;
	GPIO_InitStruct.Mode = GPIO_MODE_IT_RISING;
	GPIO_InitStruct.Pull = GPIO_NOPULL;
	HAL_GPIO_Init(MPU_int_GPIO_Port, &GPIO_InitStruct);

	/* EXTI interrupt init*/
	HAL_NVIC_SetPriority(EXTI9_5_IRQn, 0, 0);
	HAL_NVIC_EnableIRQ(EXTI9_5_IRQn);

}

 /**
  * @brief  Period elapsed callback in non blocking mode
  * @note   This function is called  when TIM1 interrupt took place, inside
  * HAL_TIM_IRQHandler(). It makes a direct call to HAL_IncTick() to increment
  * a global variable "uwTick" used as application time base.
  * @param  htim : TIM handle
  * @retval None
  */
void HAL_TIM_PeriodElapsedCallback(TIM_HandleTypeDef *htim)
{
	if (htim->Instance == TIM1) {
		HAL_IncTick();
	}

	if (htim->Instance == TIM3) {

	if (currentTickLeft >= ticksPerPulseLeft) {
		currentTickLeft = 0;
	}

	if (currentTickLeft == 0) {
		HAL_GPIO_WritePin(GPIOD, MOT_B_STEP_Pin, GPIO_PIN_SET);
		//PORTD |= _BV(PD7); // digitalWrite(MOT_B_STEP, HIGH);
		HAL_GPIO_WritePin(GPIOE, LD6_Pin, GPIO_PIN_SET);
	}
	else if (currentTickLeft == PULSE_WIDTH) {
		HAL_GPIO_WritePin(GPIOD, MOT_B_STEP_Pin, GPIO_PIN_RESET);
		//PORTD &= ~_BV(PD7); // digitalWrite(MOT_B_STEP, LOW);
		HAL_GPIO_WritePin(GPIOE, LD6_Pin, GPIO_PIN_RESET);
	}

	currentTickLeft++;

	if (currentTickRight >= ticksPerPulseRight) {
		currentTickRight = 0;
	}

	if (currentTickRight == 0) {
		HAL_GPIO_WritePin(GPIOD, MOT_A_STEP_Pin, GPIO_PIN_SET);
		//PORTB |= _BV(PB1); // digitalWrite(MOT_A_STEP, HIGH);
		HAL_GPIO_WritePin(GPIOE, LD7_Pin, GPIO_PIN_SET);
	}
	else if (currentTickRight == PULSE_WIDTH) {
		HAL_GPIO_WritePin(GPIOD, MOT_A_STEP_Pin, GPIO_PIN_RESET);
		//PORTB &= ~_BV(PB1); // digitalWrite(MOT_A_STEP, LOW);
		HAL_GPIO_WritePin(GPIOE, LD7_Pin, GPIO_PIN_RESET);
	}

	currentTickRight++;
	}
}

void HAL_I2C_MemTxCpltCallback(I2C_HandleTypeDef *hi2c)
{
	/* Prevent unused argument(s) compilation warning */
	UNUSED(hi2c);
	i2c2_transmit_complete = true;
}

void HAL_I2C_MemRxCpltCallback(I2C_HandleTypeDef *hi2c)
{
	/* Prevent unused argument(s) compilation warning */
	UNUSED(hi2c);
	i2c2_receive_complete = true;
}

void HAL_GPIO_EXTI_Callback(uint16_t GPIO_Pin)
{

	if (GPIO_Pin == GPIO_PIN_6)
	{

		mpuInterrupt = true;
	}
}

void HAL_UART_RxCpltCallback(UART_HandleTypeDef* huart)
{

	//HAL_UART_Receive_DMA(huart, rxBuffer, 64);

	//disable half transfer interrupt; it is enabled in HAL_UARTEx_ReceiveToIdle_DMA()
	//__HAL_DMA_DISABLE_IT(huart2.hdmarx, DMA_IT_HT);
}

void Error_Handler(void)
{
	__disable_irq();
	while (1)
	{
	}
}

/************************ (C) COPYRIGHT STMicroelectronics *****END OF FILE****/
